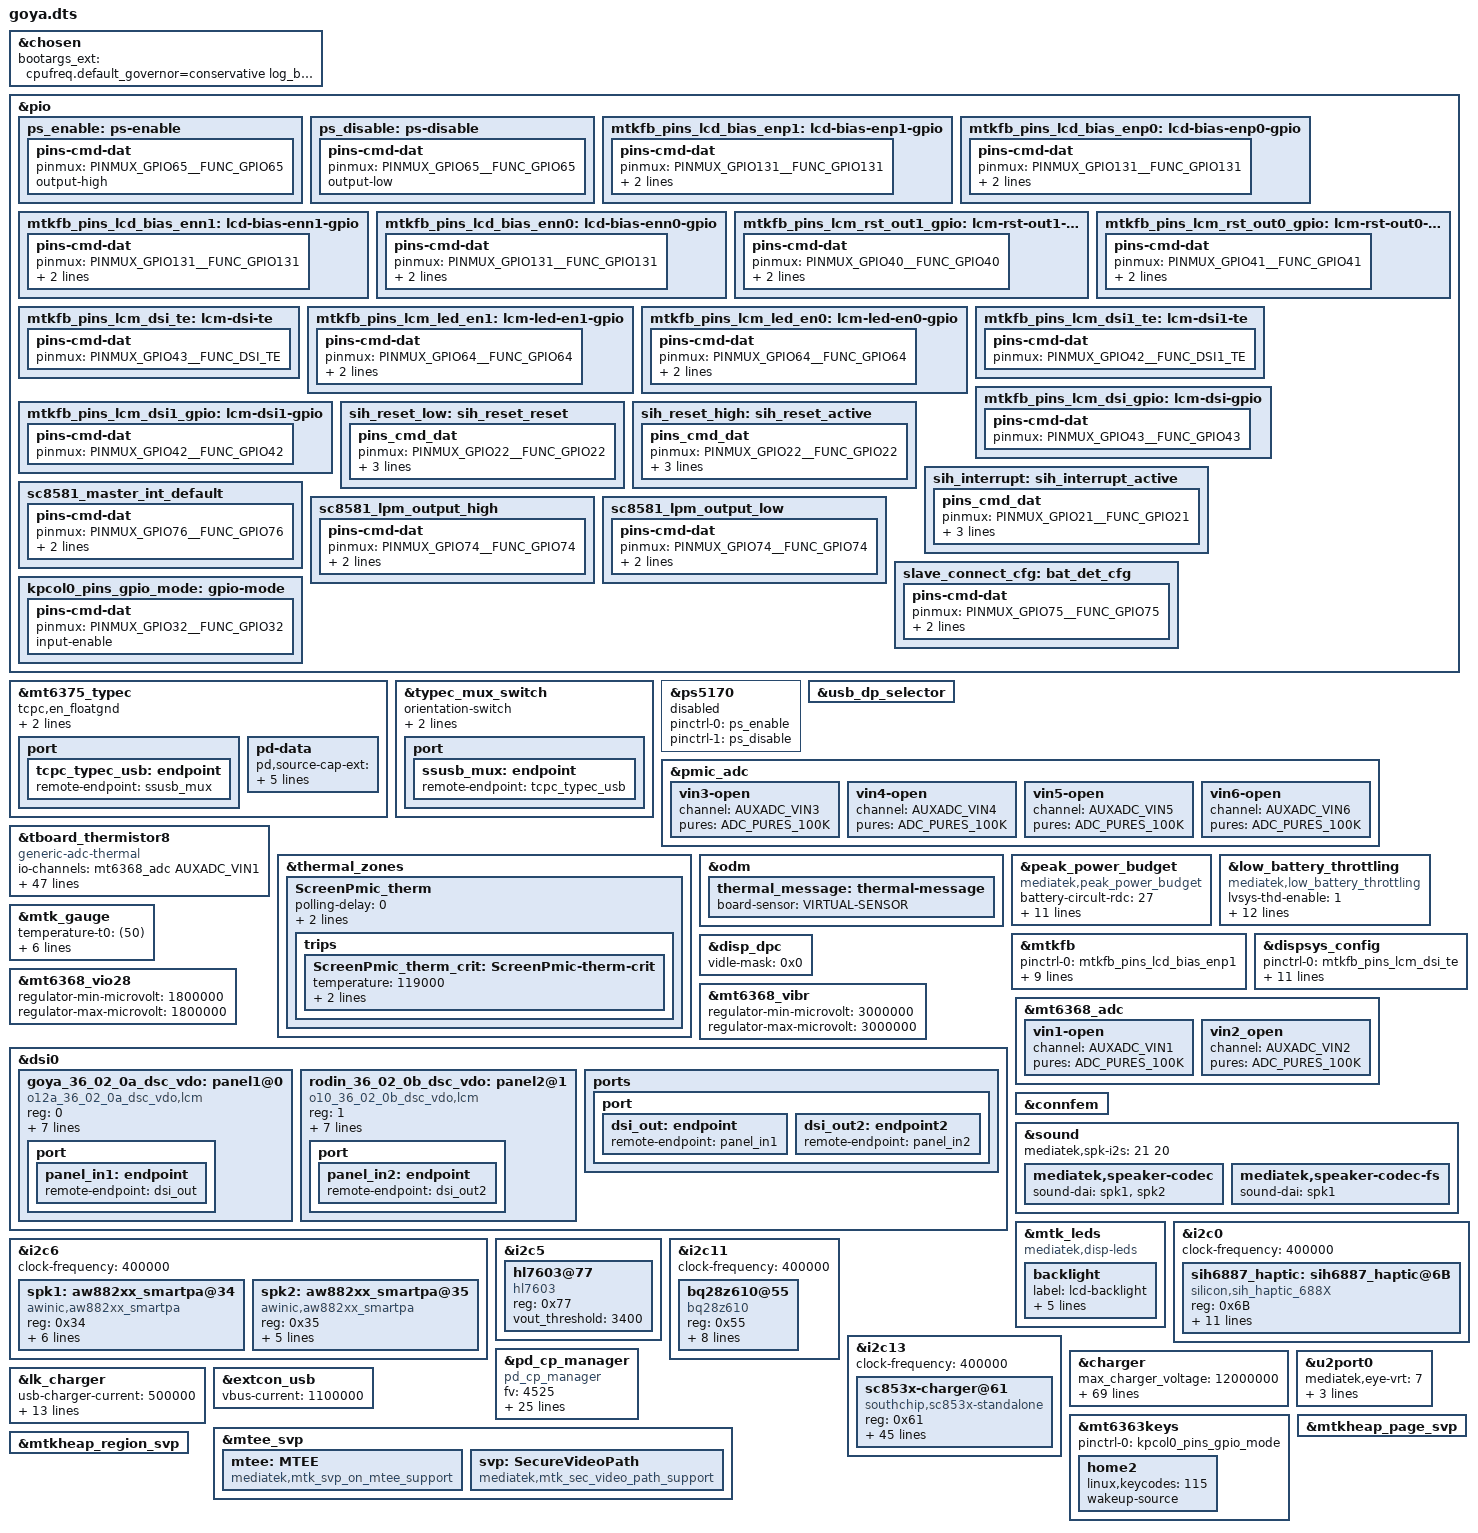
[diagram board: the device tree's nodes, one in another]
// SPDX-License-Identifier: (GPL-2.0 OR MIT)
/*
 * Copyright (C) 2022 MediaTek Inc.
 */
/dts-v1/;
/plugin/;
#include <dt-bindings/interrupt-controller/arm-gic.h>
#include <dt-bindings/interrupt-controller/irq.h>
#include <dt-bindings/phy/phy.h>
#include <dt-bindings/pinctrl/mt6899-pinfunc.h>
#include "mediatek/goya-mt6899-common.dtsi"
#include "mediatek/goya-sensor-common.dtsi"
#include <dt-bindings/iio/mt635x-auxadc.h>
#include <dt-bindings/thermal/thermal.h>
#include "mediatek/xiaomi_goya_t1_chip.dtsi"

&chosen {
	bootargs_ext = "cpufreq.default_governor=conservative \
				log_buf_len=4M";
};

/* usb typec mux start */
&pio {

	ps_enable: ps-enable {
		pins-cmd-dat {
			pinmux = <PINMUX_GPIO65__FUNC_GPIO65>;
			output-high;
		};
	};

	ps_disable: ps-disable {
		pins-cmd-dat {
			pinmux = <PINMUX_GPIO65__FUNC_GPIO65>;
			output-low;
		};
	};

};

&mt6375_typec {
	tcpc,en_floatgnd;
	/* 0:16x, 1:128x, 2:512x, 3:1024x */
	wd,wd0_tsleep = <1>;
	/* 0:400us, 1:1ms, 2:2ms, 3:4ms, 4:10ms, 5:40ms, 6:100ms, 7:400ms */
	wd,wd0_tdet = <3>;
	/* example wd0_tsleep = 512x, wd0_tdet = 4ms, wd0 polling time = 512*4ms */

	port {
		tcpc_typec_usb: endpoint {
			remote-endpoint = <&ssusb_mux>;
		};
	};

	pd-data {
		pd,source-cap-ext = /bits/ 8 <0xcf 0x29 0x75 0x63
					0x00 0x00 0x00 0x00
					0x00 0x00 0x00 0x00
					0x00 0x00 0x00 0x00
					0x00 0x00 0x00 0x00
					0x00 0x00 0x01 0x05
					0x00>;
		pd,sink-cap-ext = /bits/ 8 <0xcf 0x29 0x75 0x63
					0x00 0x00 0x00 0x00
					0x00 0x00 0x01 0x00
					0x00 0x00 0x00 0x00
					0x01 0x0b 0x01 0x37
					0x37 0x00 0x00 0x00>;

		pd,sink-pdo-data = <0x0001912c 0x0002d12c 0xc0dc2464>;
	};
};

&typec_mux_switch {
	orientation-switch;
	mode-switch;
	accessory;
	port {
		ssusb_mux: endpoint {
			remote-endpoint = <&tcpc_typec_usb>;
		};
	};
};

&ps5170 {
	pinctrl-names = "enable", "disable";
	pinctrl-0 = <&ps_enable>;
	pinctrl-1 = <&ps_disable>;
	status = "disable";
};

&usb_dp_selector {
	status = "okay";
};
/* usb typec mux end */

&pmic_adc {
	vin3-open {
		channel = <AUXADC_VIN3>;
		pures = <ADC_PURES_100K>;
	};
	vin4-open {
		channel = <AUXADC_VIN4>;
		pures = <ADC_PURES_100K>;
	};
	vin5-open {
		channel = <AUXADC_VIN5>;
		pures = <ADC_PURES_100K>;
	};
	vin6-open {
		channel = <AUXADC_VIN6>;
		pures = <ADC_PURES_100K>;
	};
};

&tboard_thermistor8 {
	compatible = "generic-adc-thermal";
	#thermal-sensor-cells = <0>;
	io-channels = <&mt6368_adc AUXADC_VIN1>;
	io-channel-names = "sensor-channel";
	temperature-lookup-table =
		<(-40000) 1799>,
		<(-39000) 1797>,
		<(-38000) 1794>,
		<(-37000) 1790>,
		<(-36000) 1787>,
		<(-35000) 1783>,
		<(-34000) 1779>,
		<(-33000) 1775>,
		<(-32000) 1771>,
		<(-31000) 1766>,
		<(-30000) 1761>,
		<(-29000) 1756>,
		<(-28000) 1751>,
		<(-27000) 1745>,
		<(-26000) 1739>,
		<(-25000) 1733>,
		<(-24000) 1726>,
		<(-23000) 1719>,
		<(-22000) 1712>,
		<(-21000) 1705>,
		<(-20000) 1696>,
		<(-19000) 1688>,
		<(-18000) 1678>,
		<(-17000) 1669>,
		<(-16000) 1659>,
		<(-15000) 1649>,
		<(-14000) 1640>,
		<(-13000) 1628>,
		<(-12000) 1617>,
		<(-11000) 1605>,
		<(-10000) 1592>,
		<(-9000) 1580>,
		<(-8000) 1567>,
		<(-7000) 1554>,
		<(-6000) 1539>,
		<(-5000) 1526>,
		<(-4000) 1509>,
		<(-3000) 1493>,
		<(-2000) 1477>,
		<(-1000) 1460>,
		<0 1445>,
		<1000 1427>,
		<2000 1409>,
		<3000 1391>,
		<4000 1373>,
		<5000 1354>,
		<6000 1335>,
		<7000 1314>,
		<8000 1295>,
		<9000 1276>,
		<10000 1255>,
		<11000 1233>,
		<12000 1212>,
		<13000 1190>,
		<14000 1169>,
		<15000 1147>,
		<16000 1125>,
		<17000 1104>,
		<18000 1082>,
		<19000 1059>,
		<20000 1039>,
		<21000 1016>,
		<22000 993>,
		<23000 971>,
		<24000 942>,
		<25000 920>,
		<26000 899>,
		<27000 878>,
		<28000 856>,
		<29000 835>,
		<30000 814>,
		<31000 794>,
		<32000 773>,
		<33000 753>,
		<34000 733>,
		<35000 714>,
		<36000 694>,
		<37000 676>,
		<38000 656>,
		<39000 638>,
		<40000 620>,
		<41000 602>,
		<42000 587>,
		<43000 570>,
		<44000 551>,
		<45000 534>,
		<46000 518>,
		<47000 503>,
		<48000 488>,
		<49000 473>,
		<50000 459>,
		<51000 444>,
		<52000 431>,
		<53000 417>,
		<54000 404>,
		<55000 392>,
		<56000 379>,
		<57000 368>,
		<58000 356>,
		<59000 345>,
		<60000 334>,
		<61000 323>,
		<62000 313>,
		<63000 303>,
		<64000 293>,
		<65000 284>,
		<66000 275>,
		<67000 266>,
		<68000 258>,
		<69000 250>,
		<70000 242>,
		<71000 234>,
		<72000 226>,
		<73000 219>,
		<74000 212>,
		<75000 206>,
		<76000 199>,
		<77000 193>,
		<78000 187>,
		<79000 181>,
		<80000 175>,
		<81000 169>,
		<82000 164>,
		<83000 159>,
		<84000 154>,
		<85000 149>,
		<86000 144>,
		<87000 140>,
		<88000 136>,
		<89000 131>,
		<90000 127>,
		<91000 123>,
		<92000 120>,
		<93000 116>,
		<94000 112>,
		<95000 109>,
		<96000 105>,
		<97000 102>,
		<98000 99>,
		<99000 96>,
		<100000 93>,
		<101000 90>,
		<102000 88>,
		<103000 85>,
		<104000 82>,
		<105000 80>,
		<106000 78>,
		<107000 75>,
		<108000 73>,
		<109000 71>,
		<110000 69>,
		<111000 67>,
		<112000 65>,
		<113000 63>,
		<114000 61>,
		<115000 59>,
		<116000 58>,
		<117000 56>,
		<118000 55>,
		<119000 53>,
		<120000 51>,
		<121000 50>,
		<122000 49>,
		<123000 47>,
		<124000 46>,
		<125000 45>;
};

&thermal_zones {
	ScreenPmic_therm: ScreenPmic_therm {
		polling-delay = <0>; /* milliseconds */
		polling-delay-passive = <0>; /* milliseconds */
		thermal-sensors = <&tboard_thermistor8>;

		trips {
			ScreenPmic_therm_crit: ScreenPmic-therm-crit {
				temperature = <119000>;
				hysteresis = <2000>;
				type = "passive";
			};
		};
	};
};

&odm {
	thermal_message: thermal-message {
		board-sensor = "VIRTUAL-SENSOR";
	};
};


&peak_power_budget {
	compatible = "mediatek,peak_power_budget";

	battery-circult-rdc = <27>;
	battery0-path-rac-t0 = <57>;
	battery0-path-rac-t1 = <57>;
	battery0-path-rac-t2 = <57>;
	battery0-path-rac-t3 = <57>;
	battery0-path-rac-t4 = <57>;
	battery0-path-rac-t5 = <57>;
	max-temperature-stage = <5>;
	temperature-threshold = <50 25 10 0 0xFFFFFFF6>;
	system-ocp = <13000>;
	system-uvlo = <2400>;
	bat-ocv-table-num = <0>;
};

&low_battery_throttling {
	compatible = "mediatek,low_battery_throttling";
	lvsys-thd-enable = <1>;
	vbat-thd-enable = <1>;
	bat0-thd-volts-l = <
		3325 3100 2900
		3450 3100 2900
		3699 3100 2900
		4323 3272 2988>;
	bat0-thd-volts-h = <
		3425 3325 3100
		3550 3450 3100
		3799 3699 3100
		4423 4323 3272>;
	bat1-thd-volts-l = <
		3325 3100 2900
		3450 3100 2900
		3699 3100 2900
		4323 3272 2988>;
	bat1-thd-volts-h = <
		3425 3325 3100
		3550 3450 3100
		3799 3699 3100
		4423 4323 3272>;
	lvsys-thd-volt-l = <2900>;
	lvsys-thd-volt-h = <3100>;
	temperature-stage-threshold = <25 10 0>;
};

&mtk_gauge {
	temperature-t0 = <(50)>;
	/* Battery temperature T0 */
	temperature-t1 = <(25)>;
	/* Battery temperature T1 */
	temperature-t2 = <(10)>;
	/* Battery temperature T2 */
	temperature-t3 = <(0)>;
	/* Battery temperature T3 */
	temperature-t4 = <(-10)>;
	/* Battery temperature T4 */
	active-table = <(5)>;
	#include "goya_mt6899_battery_table.dtsi"
};

&pio {
	mtkfb_pins_lcd_bias_enp1: lcd-bias-enp1-gpio {
		pins-cmd-dat {
			pinmux = <PINMUX_GPIO131__FUNC_GPIO131>;
			slew-rate = <1>;
			output-high;
		};
	};

	mtkfb_pins_lcd_bias_enp0: lcd-bias-enp0-gpio {
		pins-cmd-dat {
			pinmux = <PINMUX_GPIO131__FUNC_GPIO131>;
			slew-rate = <1>;
			output-low;
		};
	};

	mtkfb_pins_lcd_bias_enn1: lcd-bias-enn1-gpio {
		pins-cmd-dat {
			pinmux = <PINMUX_GPIO131__FUNC_GPIO131>;
			slew-rate = <1>;
			output-high;
		};
	};

	mtkfb_pins_lcd_bias_enn0: lcd-bias-enn0-gpio {
		pins-cmd-dat {
			pinmux = <PINMUX_GPIO131__FUNC_GPIO131>;
			slew-rate = <1>;
			output-low;
		};
	};

	mtkfb_pins_lcm_rst_out1_gpio: lcm-rst-out1-gpio {
		pins-cmd-dat {
			pinmux = <PINMUX_GPIO40__FUNC_GPIO40>;
			slew-rate = <1>;
			output-high;
		};
	};

	mtkfb_pins_lcm_rst_out0_gpio: lcm-rst-out0-gpio {
		pins-cmd-dat {
			pinmux = <PINMUX_GPIO41__FUNC_GPIO41>;
			slew-rate = <1>;
			output-low;
		};
	};

	mtkfb_pins_lcm_dsi_te: lcm-dsi-te {
		pins-cmd-dat {
			pinmux = <PINMUX_GPIO43__FUNC_DSI_TE>;
		};
	};

	mtkfb_pins_lcm_led_en1: lcm-led-en1-gpio {
		pins-cmd-dat {
			pinmux = <PINMUX_GPIO64__FUNC_GPIO64>;
			slew-rate = <1>;
			output-high;
		};
	};

	mtkfb_pins_lcm_led_en0: lcm-led-en0-gpio {
		pins-cmd-dat {
			pinmux = <PINMUX_GPIO64__FUNC_GPIO64>;
			slew-rate = <1>;
			output-low;
		};
	};

	mtkfb_pins_lcm_dsi1_te: lcm-dsi1-te {
		pins-cmd-dat {
			pinmux = <PINMUX_GPIO42__FUNC_DSI1_TE>;
		};
	};

	mtkfb_pins_lcm_dsi_gpio: lcm-dsi-gpio {
		pins-cmd-dat {
			pinmux = <PINMUX_GPIO43__FUNC_GPIO43>;
		};
	};

	mtkfb_pins_lcm_dsi1_gpio: lcm-dsi1-gpio {
		pins-cmd-dat {
			pinmux = <PINMUX_GPIO42__FUNC_GPIO42>;
		};
	};
};
&mtkfb {
	pinctrl-names = "lcd_bias_enp1_gpio", "lcd_bias_enp0_gpio",
		"lcd_bias_enn1_gpio", "lcd_bias_enn0_gpio",
		"lcm_rst_out1_gpio", "lcm_rst_out0_gpio",
		"mode_te_te", "lcm_led_en1_gpio", "lcm_led_en0_gpio",
		"mode_te_te1";
	pinctrl-0 = <&mtkfb_pins_lcd_bias_enp1>;
	pinctrl-1 = <&mtkfb_pins_lcd_bias_enp0>;
	pinctrl-2 = <&mtkfb_pins_lcd_bias_enn1>;
	pinctrl-3 = <&mtkfb_pins_lcd_bias_enn0>;
	pinctrl-4 = <&mtkfb_pins_lcm_rst_out1_gpio>;
	pinctrl-5 = <&mtkfb_pins_lcm_rst_out0_gpio>;
	pinctrl-6 = <&mtkfb_pins_lcm_dsi_te>;
	pinctrl-7 = <&mtkfb_pins_lcm_led_en1>;
	pinctrl-8 = <&mtkfb_pins_lcm_led_en0>;
	pinctrl-9 = <&mtkfb_pins_lcm_dsi1_te>;

	status = "okay";
};

&dispsys_config {
	pinctrl-names = "mode_te_te", "mode_te_te1";
	pinctrl-0 = <&mtkfb_pins_lcm_dsi_te>;
	pinctrl-1 = <&mtkfb_pins_lcm_dsi1_te>;
	status = "okay";
	lk_mode_index = <0>;
	no_hwc_layers = <2>;
	no_hwc_overlap = <1>;
	bypass-pc-path = <1>;

	helper-value = <0>, /*MTK_DRM_OPT_STAGE*/
				<1>, /*MTK_DRM_OPT_USE_CMDQ*/
				<1>, /*MTK_DRM_OPT_USE_M4U*/
				<1>, /*MTK_DRM_OPT_MMQOS_SUPPORT*/
				<1>, /*MTK_DRM_OPT_MMDVFS_SUPPORT*/
				<0>, /*MTK_DRM_OPT_SODI_SUPPORT*/
				<1>, /*MTK_DRM_OPT_IDLE_MGR*/
				<0>, /*MTK_DRM_OPT_IDLEMGR_SWTCH_DECOUPLE*/
				<1>, /*MTK_DRM_OPT_IDLEMGR_BY_REPAINT*/
				<0>, /*MTK_DRM_OPT_IDLEMGR_ENTER_ULPS*/
				<0>, /*MTK_DRM_OPT_IDLEMGR_KEEP_LP11*/
				<0>, /*MTK_DRM_OPT_DYNAMIC_RDMA_GOLDEN_SETTING*/
				<1>, /*MTK_DRM_OPT_IDLEMGR_DISABLE_ROUTINE_IRQ*/
				<1>, /*MTK_DRM_OPT_IDLEMGR_ASYNC*/
				<0>, /*MTK_DRM_OPT_MET_LOG*/
				<1>, /*MTK_DRM_OPT_USE_PQ*/
				<1>, /*MTK_DRM_OPT_ESD_CHECK_RECOVERY*/
				<1>, /*MTK_DRM_OPT_ESD_CHECK_SWITCH*/
				<1>, /*MTK_DRM_OPT_PRESENT_FENCE*/
				<0>, /*MTK_DRM_OPT_RDMA_UNDERFLOW_AEE*/
				<1>, /*MTK_DRM_OPT_DSI_UNDERRUN_AEE*/
				<1>, /*MTK_DRM_OPT_DSI_UNDERRUN_AEE_V2*/
				<0>, /*MTK_DRM_OPT_ODDMR_UNDERRUN_AEE*/
				<1>, /*MTK_DRM_OPT_HRT*/
				<1>, /*MTK_DRM_OPT_HRT_MODE*/
				<0>, /*MTK_DRM_OPT_DELAYED_TRIGGER*/
				<1>, /*MTK_DRM_OPT_OVL_EXT_LAYER*/
				<1>, /*MTK_DRM_OPT_AOD*/
				<1>, /*MTK_DRM_OPT_RPO*/
				<0>, /*MTK_DRM_OPT_DUAL_PIPE*/
				<0>, /*MTK_DRM_OPT_DC_BY_HRT*/
				<1>, /*MTK_DRM_OPT_OVL_WCG*/
				<0>, /*MTK_DRM_OPT_OVL_SBCH*/
				<1>, /*MTK_DRM_OPT_COMMIT_NO_WAIT_VBLANK*/
				<0>, /*MTK_DRM_OPT_MET*/
				<0>, /*MTK_DRM_OPT_REG_PARSER_RAW_DUMP*/
				<0>, /*MTK_DRM_OPT_VP_PQ*/
				<0>, /*MTK_DRM_OPT_GAME_PQ*/
				<0>, /*MTK_DRM_OPT_MMPATH*/
				<0>, /*MTK_DRM_OPT_HBM*/
				<0>, /*MTK_DRM_OPT_VDS_PATH_SWITCH*/
				<0>, /*MTK_DRM_OPT_LAYER_REC*/
				<1>, /*MTK_DRM_OPT_CLEAR_LAYER*/
				<1>, /*MTK_DRM_OPT_LFR*/
				<0>, /*MTK_DRM_OPT_SF_PF*/
				<0>, /*MTK_DRM_OPT_DYN_MIPI_CHANGE*/
				<0>, /*MTK_DRM_OPT_PRIM_DUAL_PIPE*/
				<0>, /*MTK_DRM_OPT_MSYNC2_0*/
				<1>, /*MTK_DRM_OPT_MML_PRIMARY*/
				<1>, /*MTK_DRM_OPT_MML_SUPPORT_CMD_MODE*/
				<1>, /*MTK_DRM_OPT_MML_PQ*/
				<1>, /*MTK_DRM_OPT_MML_IR*/
				<0>, /*MTK_DRM_OPT_DUAL_TE*/
				<1>, /*MTK_DRM_OPT_RES_SWITCH*/
				<1>, /*MTK_DRM_OPT_RES_SWITCH_ON_AP*/
				<0>, /*MTK_DRM_OPT_PREFETCH_TE*/
				<0>, /*MTK_DRM_OPT_VIDLE_APSRC_OFF*/
				<0>, /*MTK_DRM_OPT_VIDLE_DSI_PLL_OFF*/
				<0>, /*MTK_DRM_OPT_CHECK_TRIGGER_MERGE*/
				<0>, /*MTK_DRM_OPT_VIRTUAL_DISP*/
				<1>, /*MTK_DRM_OPT_OVL_BW_MONITOR*/
				<0>, /*MTK_DRM_OPT_GPU_CACHE*/
				<1>, /*MTK_DRM_OPT_SPHRT*/
				<0>, /*MTK_DRM_OPT_SDPA_OVL_SWITCH*/
				<0>, /*MTK_DRM_OPT_HRT_BY_LARB*/
				<1>, /*MTK_DRM_OPT_MAX_CHANNEL_HRT*/
				<0>, /*MTK_DRM_OPT_TILE_OVERHEAD*/
				<0>, /*MTK_DRM_OPT_VIDLE_TOP_EN*/
				<0>, /*MTK_DRM_OPT_VIDLE_MTCMOS_DT_EN*/
				<0>, /*MTK_DRM_OPT_VIDLE_MMINFRA_DT_EN*/
				<0>, /*MTK_DRM_OPT_VIDLE_DVFS_DT_EN*/
				<0>, /*MTK_DRM_OPT_VIDLE_QOS_DT_EN*/
				<0>, /*MTK_DRM_OPT_VIDLE_GCE_TS_EN*/
				<0>, /*MTK_DRM_OPT_DPC_PRE_TE_EN*/
				<1>, /*MTK_DRM_OPT_PARTIAL_UPDATE*/
				<0>, /*MTK_DRM_OPT_SLC_ALL_CACHE*/
				<1>, /*MTK_DRM_OPT_OVL_WCG_BY_COLOR_MODE*/
				<0>; /*"MTK_DRM_OPT_OVLSYS_CASCADE"*/
};

&disp_dpc {
	vidle-mask = <0x0>;
};

&mt6368_vio28 {
	regulator-min-microvolt = <1800000>;
	regulator-max-microvolt = <1800000>;
};

&mt6368_vibr {
	regulator-min-microvolt = <3000000>;
	regulator-max-microvolt = <3000000>;
};

&dsi0 {
	status = "okay";
	#address-cells = <1>;
	#size-cells = <0>;
	goya_36_02_0a_dsc_vdo: panel1@0 {
		compatible = "o12a_36_02_0a_dsc_vdo,lcm";
		reg = <0>;
		pm-enable-gpios = <&pio 64 0>;
		reset-gpios = <&pio 41 0>;
		mi,esd-err-irq-gpio = <&pio 122 0x2002>;
		vio18-supply = <&mt6368_vio28>;
		vibr30-supply = <&mt6368_vibr>;
		dvdd-gpios = <&pio 131 0>;
		gate-ic = <4831>;
		pinctrl-names = "default";
		port {
			panel_in1: endpoint {
				remote-endpoint = <&dsi_out>;
			};
		};
	};
	rodin_36_02_0b_dsc_vdo: panel2@1 {
		compatible = "o10_36_02_0b_dsc_vdo,lcm";
		reg = <1>;
		pm-enable-gpios = <&pio 64 0>;
		reset-gpios = <&pio 41 0>;
		mi,esd-err-irq-gpio = <&pio 122 0x2002>;
		vio18-supply = <&mt6368_vio28>;
		vibr30-supply = <&mt6368_vibr>;
		dvdd-gpios = <&pio 72 0>;
		gate-ic = <4831>;
		pinctrl-names = "default";
		port {
			panel_in2: endpoint {
				remote-endpoint = <&dsi_out2>;
			};
		};
	};
	ports {
		port {
			dsi_out: endpoint {
				remote-endpoint = <&panel_in1>;
			};
			dsi_out2: endpoint2 {
				remote-endpoint = <&panel_in2>;
			};
		};
	};
};


&mt6368_adc {
	vin1-open {
		channel = <AUXADC_VIN1>;
		pures = <ADC_PURES_100K>;
	};
	vin2_open {
		channel = <AUXADC_VIN2>;
		pures = <ADC_PURES_100K>;
	};
};

&connfem {
/* Enable epa_elna node to support Wifi & BT ePA/eLNA FEM on customer load */
#if 0
	epa-elna {
		parts = <&wlan7207h &wlan7207c>;
		wifi {
			flags-0 {
				open-loop;
			};
		};
		bt {
			flags-0 {
				/* choose one of: epa-elna/epa/elna/bypass */
				epa-elna;
			};
		};
	};
#endif
};

&i2c6 {
/*
	spk1: speaker_amp@5c {
		compatible = "richtek,rt5512";
		#sound-dai-cells = <0>;
		reg = <0x5c>;
		status = "okay";
		sound-name-prefix = "Left";
	};
*/
	clock-frequency = <400000>;
	spk1: aw882xx_smartpa@34 {
		compatible = "awinic,aw882xx_smartpa";
		#sound-dai-cells = <0>;
		reg = <0x34>;
		reset-gpio = <&pio 64 0>;
		irq-gpio = <&pio 19 0x0>;
		spk-sw-gpio = <&pio 23 0x0>;
		sound-channel = <0>;
		aw-re-min = <5500>;
		aw-re-max= <8000>;
		/*aw-cali-mode = "none";*/
		status = "okay";
	};
	spk2: aw882xx_smartpa@35 {
		compatible = "awinic,aw882xx_smartpa";
		#sound-dai-cells = <0>;
		reg = <0x35>;
		reset-gpio = <&pio 63 0>;
		irq-gpio = <&pio 20 0x0>;
		sound-channel = <1>;
		aw-re-min = <5000>;
		aw-re-max= <7500>;
		/*aw-cali-mode = "none";*/
		status = "okay";
	};
};

&sound {
	mediatek,spk-i2s = <21 20>;
	mediatek,speaker-codec {
		sound-dai = <&spk1>, <&spk2>;
	};
	mediatek,speaker-codec-fs {
		sound-dai = <&spk1>;
	};
};

&mtk_leds {
	compatible = "mediatek,disp-leds";

	backlight {
		label = "lcd-backlight";
		max-brightness = <16383>;
		min-brightness = <1>;
		max-hw-brightness = <16383>;
		led-mode = <4>;
		default-state = "FifteenPercent";
	};
};

#if 0
&mtk_leds {
	compatible = "mediatek,disp-leds";

	backlight {
		label = "lcd-backlight";
		max-brightness = <4095>;
		min-brightness = <4>;
		max-hw-brightness = <4095>;
		led-mode = <4>;
		default-state = "quarter";
	};
};

&pdc {
	pd-vbus-upper-bound = <9000000>;
};

&dsi1 {
//	status = "okay";
	#address-cells = <1>;
	#size-cells = <0>;
	init-panel-off;
	panel1@0 {
		compatible = "truly,td4330,cmd";
		reg = <0>;
		pm-enable-gpios = <&pio 215 0>;
		reset-gpios = <&pio 9 0>;
		swap-from-dts;
		lane-swap-setting = <1 2 0 3 4 2>;
		pn-swap-setting = <1 1 1 1 1 1>;
		gate-ic = <4831>;
		pinctrl-names = "default";
		port {
			panel1_in: endpoint {
				remote-endpoint = <&dsi1_out>;
			};
		};
	};
	panel2@1 {
		compatible = "jdi,nt36672e,vdo,120hz";
		reg = <1>;
		pm-enable-gpios = <&pio 215 0>;
		reset-gpios = <&pio 9 0>;
		swap-from-dts;
		gate-ic = <4831>;
		pinctrl-names = "default";
		port {
			panel2_in: endpoint {
				remote-endpoint = <&dsi1_out2>;
			};
		};
	};
	panel3@2 {
		compatible = "jdi,nt36672e,cphy,vdo";
		reg = <2>;
		pm-enable-gpios = <&pio 215 0>;
		reset-gpios = <&pio 9 0>;
		gate-ic = <4831>;
		pinctrl-names = "default";
		port {
			panel3_in: endpoint {
				remote-endpoint = <&dsi1_out3>;
			};
		};
	};
	panel4@3 {
		compatible = "jdi,nt36672e,vdo,60hz";
		reg = <3>;
		pm-enable-gpios = <&pio 215 0>;
		reset-gpios = <&pio 9 0>;
		gate-ic = <4831>;
		pinctrl-names = "default";
		port {
			panel4_in: endpoint {
				remote-endpoint = <&dsi1_out4>;
			};
		};
	};
	ports {
		port {
			dsi1_out: endpoint@0 {
				remote-endpoint = <&panel1_in>;
			};

			dsi1_out2: endpoint@1 {
				remote-endpoint = <&panel2_in>;
			};

			dsi1_out3: endpoint@2 {
				remote-endpoint = <&panel3_in>;
			};

			dsi1_out4: endpoint@3 {
				remote-endpoint = <&panel4_in>;
			};
		};
	};
};

&dsi1_te {
	interrupt-parent = <&pio>;
	interrupts = <10 1 10 1>;
	status = "okay";
};

#if 1
/* GPS GPIO standardization start */
&pio {
	gps_pins_default: gps_default {
	};
	gps_l1_lna_pins_ol: gps-l1-lna0 {
		pins-cmd-dat {
			pinmux = <PINMUX_GPIO190__FUNC_GPIO12>;
			output-low;
		};
	};
	gps_l1_lna_pins_dsp_ctrl: gps-l1-lna1 {
		pins-cmd-dat {
			pinmux = <PINMUX_GPIO190__FUNC_GPS_L1_ELNA_EN>;
		};
	};
	gps_l1_lna_pins_oh: gps-l1-lna2 {
		pins-cmd-dat {
			pinmux = <PINMUX_GPIO190__FUNC_GPIO12>;
			output-high;
		};
	};
	gps_l5_lna_pins_ol: gps-l5-lna0 {
		pins-cmd-dat {
			pinmux = <PINMUX_GPIO191__FUNC_GPIO13>;
			output-low;
		};
	};
	gps_l5_lna_pins_dsp_ctrl: gps-l5-lna1 {
		pins-cmd-dat {
			pinmux = <PINMUX_GPIO191__FUNC_GPS_L5_ELNA_EN>;
		};
	};
	gps_l5_lna_pins_oh: gps-l5-lna2 {
		pins-cmd-dat {
			pinmux = <PINMUX_GPIO191__FUNC_GPIO13>;
			output-high;
		};
	};
};
&gps {
	pinctrl-names = "default",
		"gps_l1_lna_disable",
		"gps_l1_lna_dsp_ctrl",
		"gps_l1_lna_enable",
		"gps_l5_lna_disable",
		"gps_l5_lna_dsp_ctrl",
		"gps_l5_lna_enable";
	pinctrl-0 = <&gps_pins_default>;
	pinctrl-1 = <&gps_l1_lna_pins_ol>;
	pinctrl-2 = <&gps_l1_lna_pins_dsp_ctrl>;
	pinctrl-3 = <&gps_l1_lna_pins_oh>;
	pinctrl-4 = <&gps_l5_lna_pins_ol>;
	pinctrl-5 = <&gps_l5_lna_pins_dsp_ctrl>;
	pinctrl-6 = <&gps_l5_lna_pins_oh>;
	status = "okay";
};
/* GPS GPIO standardization end */
#endif

&pcie0 {
	pinctrl-names = "default", "sleep", "work";
	pinctrl-0 = <&pcie0_pins_default>;
	pinctrl-1 = <&pcie0_pins_sleep>;
	pinctrl-2 = <&pcie0_pins_work>;
	max-link-speed = <3>;
	status = "okay";
};

&pcie1 {
	pinctrl-names = "default";
	pinctrl-0 = <&pcie1_pins_default>;
	status = "disabled";
};

&pciephy0 {
	status = "okay";
};

&pciephy1 {
	status = "disabled";
};

/* PCIe pinmux start */
&pio {
	pcie0_pins_default: pcie0-default {
		pins-cmd-dat {
			pinmux = <PINMUX_GPIO143__FUNC_GPIO143>;
			output-low;
		};

		pins-cmd-dat1 {
			pinmux = <PINMUX_GPIO144__FUNC_GPIO144>,
				 <PINMUX_GPIO145__FUNC_GPIO145>;
			bias-pull-up;
			input-enable;
		};
	};

	pcie0_pins_work: pcie0-work {
		pins-cmd-dat {
			pinmux = <PINMUX_GPIO143__FUNC_PCIE_PERSTN>,
				 <PINMUX_GPIO145__FUNC_PCIE_CLKREQN>;
			bias-pull-up;
		};

		pins-cmd-dat1 {
			pinmux = <PINMUX_GPIO144__FUNC_GPIO144>;
			bias-pull-down;
			input-enable;
		};
	};

	pcie0_pins_sleep: pcie0-sleep {
		pins-cmd-dat {
			pinmux = <PINMUX_GPIO143__FUNC_GPIO143>;
			output-low;
		};

		pins-cmd-dat1 {
			pinmux = <PINMUX_GPIO144__FUNC_GPIO144>,
				 <PINMUX_GPIO145__FUNC_GPIO145>;
			bias-pull-up;
			input-enable;
		};
	};

	pcie1_pins_default: pcie1-default {
		pins-cmd-dat {
			pinmux = <PINMUX_GPIO2__FUNC_PCIE_CLKREQN_P1>,
				 <PINMUX_GPIO3__FUNC_PCIE_WAKEN_P1>,
				 <PINMUX_GPIO4__FUNC_PCIE_PERSTN_P1>;
			bias-pull-up;
		};
	};
};
/* PCIe pinmux end */

/* usb typec mux start */
&pio {

	ps_enable: ps_enable {
		pins_cmd_dat {
			pinmux = <PINMUX_GPIO111__FUNC_GPIO111>;
			output-high;
		};
	};

	ps_disable: ps_disable {
		pins_cmd_dat {
			pinmux = <PINMUX_GPIO111__FUNC_GPIO111>;
			output-low;
		};
	};

};

&mt6375_typec {
	port {
		tcpc_typec_usb: endpoint {
			remote-endpoint = <&ssusb_mux>;
		};
	};
};

&typec_mux_switch {
	orientation-switch;
	mode-switch;
	accessory;
	port {
		ssusb_mux: endpoint {
			remote-endpoint = <&tcpc_typec_usb>;
		};
	};
};

&ps5170 {
	pinctrl-names = "enable", "disable";
	pinctrl-0 = <&ps_enable>;
	pinctrl-1 = <&ps_disable>;
	status = "disable";
};

&usb_dp_selector {
	status = "okay";
};
/* usb typec mux end */

#if 0
&pdc {
	pd_vbus_upper_bound = <12000000>;
};
#endif

&wifi {
	flavor-bin = "dx3";
};

&bt {
	flavor-bin = "dx3";
};

#endif

/* SI Haptic */
&pio {
	sih_reset_low: sih_reset_reset {
		pins_cmd_dat {
			pinmux = <PINMUX_GPIO22__FUNC_GPIO22>;
			drive-strength = <2>;
			bias-disable;
			output-low;
		};
	};
	sih_reset_high: sih_reset_active {
		pins_cmd_dat {
			pinmux = <PINMUX_GPIO22__FUNC_GPIO22>;
			drive-strength = <2>;
			bias-disable;
			output-high;
		};
	};
	sih_interrupt: sih_interrupt_active {
		pins_cmd_dat {
			pinmux = <PINMUX_GPIO21__FUNC_GPIO21>;
			drive-strength = <2>;
			bias-pull-up;
			input-enable;
		};
	};
};
/* SI Haptic */

&i2c0 {
    clock-frequency = <400000>;
	status = "ok";
	/* SI Haptic */
	sih6887_haptic:sih6887_haptic@6B{
		compatible = "silicon,sih_haptic_688X";
		reg = <0x6B>;
		reset-gpio = <&pio 22 0>;
		irq-gpio = <&pio 21 0>;
		interrupt=<26 1>;
		pinctrl-names = "sih_reset_reset","sih_reset_active","sih_interrupt_active";
		pinctrl-0 = <&sih_reset_low>;
		pinctrl-1 = <&sih_reset_high>;
		pinctrl-2 = <&sih_interrupt>;
		lra_name = "0809";
		vib_effect_id_boundary = < 10 >;
		vib_effect_max = < 197 >;
		vib_f0_pre = < 1700 >;
		vib_bst_vol_default = < 95 >;
    };
	/* SI Haptic */
};

/* charger start */
&pio {
	sc8581_master_int_default: sc8581_master_int_default {
		pins-cmd-dat {
			pinmux = <PINMUX_GPIO76__FUNC_GPIO76>;
			bias-pull-up = <MTK_PUPD_SET_R1R0_10>;
			input-enable;
		};
	};

	sc8581_lpm_output_high: sc8581_lpm_output_high {
		pins-cmd-dat {
			pinmux = <PINMUX_GPIO74__FUNC_GPIO74>;
			slew-rate = <1>;
			output-high;
		};
	};

	sc8581_lpm_output_low: sc8581_lpm_output_low {
		pins-cmd-dat {
			pinmux = <PINMUX_GPIO74__FUNC_GPIO74>;
			slew-rate = <1>;
			output-low;
		};
	};
};

&i2c5 {
	status = "ok";
	hl7603@77 {
		compatible = "hl7603";
		reg = <0x77>;
		vout_threshold = <3400>;
	};
};

&pio {
	slave_connect_cfg: bat_det_cfg {
		pins-cmd-dat {
			pinmux = <PINMUX_GPIO75__FUNC_GPIO75>;
			bias-pull-up = <MTK_PUPD_SET_R1R0_10>;
			input-enable;
		};
	};
};


&i2c11 {
	clock-frequency = <400000>;
	status = "okay";
	bq28z610@55 {
		compatible = "bq28z610";
		reg = <0x55>;
		enable_shutdown_delay;
		normal_shutdown_vbat_1s = <3400>;
 		critical_shutdown_vbat_1s = <3340>;
		report_full_rsoc_1s = <9700>;
 		soc_gap_1s = <2>;
 		slave_connect_gpio = <&pio 39 0x1>;
		soc_decimal_rate = <
 			0  38
 			10 35
 			20 33
 			30 33
 			40 33
			50 33
 			60 33
 			70 30
 			80 25
 			90 20
 			95 10 >;
	};
};

&i2c13 {
	clock-frequency = <400000>;
	status = "okay";
	sc853x-charger@61{
		compatible = "southchip,sc853x-standalone";
		reg = <0x61>;
		sc853x,intr_gpio = <&pio 76 IRQ_TYPE_EDGE_FALLING>;
		charger_name = "primary_dvchg";
		charger_name_v4_19 = "primary_dvchg";

		sc,sc853x,vbat-ovp-dis = <0>;
		sc,sc853x,vbat-ovp = <90>; /*3840 + val * 10*/
		sc,sc853x,ibat-ocp-dis = <1>;
		sc,sc853x,ibat-ocp = <100>; /*val * 100*/
		sc,sc853x,vbus-ovp-dis = <0>;
		sc,sc853x,vbus-ovp = <7>; /*9250 + val * 250*/
		sc,sc853x,vac-ovp-dis = <0>;
		sc,sc853x,vac-ovp = <2>; /*0:6.5V 1:11V 2:12V 3:13V 4:14V 5~7:15V*/
		sc,sc853x,ibus-ocp-dis = <1>;
		sc,sc853x,ibus-ocp = <125>; /*val * 50*/
		sc,sc853x,pmid2out-ovp-dis = <0>;
		sc,sc853x,pmid2out-ovp = <2>; /*400 + val * 100*/
		sc,sc853x,pmid2out-uvp-dis = <0>;
		sc,sc853x,pmid2out-uvp = <3>; /*100 + val * 50*/
		sc,sc853x,ibatreg = <0>; /*200 + val * 100*/
		sc,sc853x,ibusreg = <0>; /*100 + val * 50*/
		sc,sc853x,vbatreg = <0>; /*50 + val * 50*/
		sc,sc853x,tdiereg = <3>; /*0:90°C 1:100°C 2:110°C 3:120°C*/
		sc,sc853x,them-flt = <24>; /*val * 25*/
		sc,sc853x,ibat-sns-res = <0>; /*0:2hmo 1:5hmo*/
		sc,sc853x,pmid-pd-en = <0>;
		sc,sc853x,vbus-pd-en = <0>;
		sc,sc853x,work-mode = <0>; /*0: 2:1charge   1: 1:1charge
									 2: 1:2converte 3: 1:1converte*/
		sc,sc853x,ss-timeout = <7>; /*0:disable 1:10ms 2:20ms 3:400ms
									4:80ms 5:320ms 6:1.28s 7:10.24s*/
		sc,sc853x,wd-timeout-dis = <1>;
		sc,sc853x,wd-timeout = <0>; /*0:0.5s 1:1s 2:5s 3:30s*/
		sc,sc853x,vout-ovp-dis = <0>;
		sc,sc853x,vout-ovp = <3>; /*4700 + val * 100*/
		sc,sc853x,fsw-freq = <7>; /*500 + val * 100*/
		sc,sc853x,pin-diag-fall-dis = <0>;
		sc,sc853x,them-flt-dis = <1>;
		sc,sc853x,tshut-dis = <1>;
		sc,sc853x,vbus-in-range-dis = <0>;
		sc,sc853x,ibus-ucp-dis = <0>;
		sc,sc853x,ibat-reg-dis = <0>;
		sc,sc853x,ibus-reg-dis = <0>;
		sc,sc853x,vbat-reg-dis = <0>;
		sc,sc853x,tdie-reg-dis = <1>;
		sc,sc853x,ibat-ocp-dg = <0>; /*0:160us 1:80us 2:320us 3:5ms*/
		sc,sc853x,ibus-ucp-fall-dg = <1>; /*0:8us 1:5ms 2:40ms 3:160ms*/
		sc,sc853x,ibus-ocp-dg = <0>; /*0:160us 1:80us 2:320us 3:5ms*/
		sc,sc853x,vbat-ovp-dg = <0>; /*0:8us 1:160us 2:320us 3:5ms*/
	};
};

&charger {
		max_charger_voltage = <12000000>;
		fv = <4530>;
		fv_normal = <4510>;
		fv_ffc = <4580>;
		iterm = <295>;
		iterm_warm = <295>;
		/* charging current */
		usb_charger_current = <500000>;
		ac_charger_current = <1600000>;
		ac_charger_input_current = <1600000>;
		charging_host_charger_current = <900000>;
		ffc_low_tbat = <200>;
		ffc_medium_tbat = <300>;
		ffc_warm_tbat = <350>;
		ffc_little_high_tbat = <400>;
		ffc_high_tbat = <480>;
		ffc_high_soc = <95>;
		adapter_power = <67>;
		step_fallback_hyst = <25>;
		step_forward_hyst = <5>;
		jeita_fallback_hyst = <10>;
		jeita_forward_hyst = <10>;
		mt6368_moscon1_control;
		en_floatgnd;
		rust_support;
		enable_pdtest_mode = <1>;
		pd2_input_current = <1700000>;
		min_charger_voltage_1 = <4600000>;
		min_charger_voltage_2 = <4600000>;
		sbu_uart_en = <&pio 24 0x0>;
		jeita_fcc_cfg = <(-100)	30	4200	900	753
				31	80	4530	2575	2575
				81	130	4530	3645	3645
				131	200	4530	6320	6320
				201	470	4150	12400	12400
				471	600	4100	2575	2575>;
		jeita_fv_cfg = <(-100)	30	4530
				31	80	4530
				81	130	4530
				131	200	4530
				201	470	4580
				471	600	4100>;

		iterm_ffc_1_cycle = <1773>;
		iterm_ffc_little_warm_1_cycle = <2303>;
		iterm_ffc_warm_1_cycle = <2657>;
		iterm_ffc_hot_1_cycle = <3012>;

		step_chg_cfg_1_cycle = <3000	4150	12300
					4151	4300	9530
					4301	4480	7925
					4481	4580	6320>;

		step_chg_cfg_100_cycle = <3000	4120	12300
					4121	4270	9530
					4271	4460	7925
					4461	4560	6320>;

		step_chg_cfg_300_cycle = <3000  4120    12300
					4121    4270    9530
					4271    4450    7925
					4451    4550    6320>;

		step_chg_cfg_800_cycle = <3000  4120    9820
					4121    4270    7604
					4271    4450    6320
					4451    4550    5036>;

		step_chg_cfg_1000_cycle = <3000	4100	9820
					4101	4250	7604
					4251	4430	6320
					4431	4550	5036>;

		thermal_limit_dcp = <1900 1900 1900 1900 1900 1900 1900 1900 1900 1900 1900 1900 1500 1400 1200 500>;
		thermal_limit_qc2 = <2500 2500 2500 2500 2500 2500 2500 2500 2500 2500 2500 2000 1500 1500 1000 500>;
		thermal_limit_qc3_18w = <2500 2500 2500 2500 2500 2500 2400 2300 2200 2100 1500 1000 800 700 600 500>;
		thermal_limit_qc3_27w = <2500 2500 2500 2500 2500 2500 2400 2300 2200 2100 1500 1000 800 700 600 500>;
		thermal_limit_qc35 = <2500 2500 2500 2500 2500 2500 2400 2300 2200 2100 1500 1000 800 700 600 500>;
		thermal_limit_pd = <12400 10000 8800 8000 6600 6000 5500 5000 4400 3000 2600 2200 1900 1500 1000 300>;

		smart_bypass_support;
		smart_bypass_entry_soc = <20>;
		smart_bypass_exit_soc = <90>;
		smart_bypass_fallback_hyst = <5>; // board_temp(0.1 degree) hyst
		smart_bypass_forward_hyst = <5>;
		smart_bypass_high_lmt_cfg = <(-100)	250	3000
				251	280	2500
				281	300	2000
				301	330	1600
				331	370	1200
				371	800	900>;
		smart_bypass_med_lmt_cfg = <(-100)	150	12400
				151	200	12400
				201	250	12400
				251	300	6000
				301	370	4400
				371	800	1900>;
		smart_bypass_low_lmt_cfg = <(-100)	150	12400
				151	200	12400
				201	250	12400
				251	300	12400
				301	370	12400
				371	800	12400>;
};

&lk_charger {
 	/* charging current */
 	usb-charger-current = <500000>;
 	ac-charger-current = <1500000>;
 	ac-charger-input-current = <2000000>;
 	non-std-ac-charger-current = <1500000>;
 	charging-host-charger-current = <1500000>;
 	ta-ac-charger-current = <1500000>;
 	pd-charger-current = <1500000>;
 	/* battery temperature protection */
 	temp-t4-threshold = <60>;
 	temp-t3-threshold = <45>;
 	pre-charger-current = <400000>;
 	fast-charge-voltage = <3100>;
 	max-charger-voltage = <12000000>;
 	shutdown-voltage = <3200>;
	boot-battery-voltage = <3400000>;
};

&pd_cp_manager {
	compatible = "pd_cp_manager";
	fv = <4525>;
	fv_ffc = <4572>;
	max_fcc = <12400>;
	max_vbus = <12000>;
	max_ibus = <6200>;
	fcc_low_hyst = <150>;
	fcc_high_hyst = <10>;
	low_tbat = <100>;
	high_tbat = <480>;
	high_vbat = <4400>;
	high_soc = <95>;
	low_fcc = <2000>;
	cv_vbat = <4510>;
	cv_vbat_ffc = <4580>;
	cv_ibat = <2000>;
	cv_ibat_bypass = <1300>;
	vbus_low_gap_div = <400>;
	vbus_high_gap_div = <600>;
	min_pdo_vbus = <8000>;
	max_pdo_vbus = <11000>;
//	mt6375_control_gpio = <&pio 77 0x0>;
	support_pmic_parachg;
	switch1_1_enter = <3000>;
	switch1_1_exit = <4000>;
	pdm_ibus_gap = <600>;
	pdm_bypass_ibus_gap = <2600>;
	adapter_power = <67>;
};

&mtk_gauge {
	DISABLE_MTKBATTERY = <(1)>;
};

&u2port0{
	mediatek,eye-vrt = <7>;
	mediatek,eye-term = <7>;
	mediatek,rev6 = <1>;
	mediatek,discth = <0xb>;
};

&extcon_usb {
	vbus-current = <1100000>;
};
/* charger end */

&mt6363keys {
  pinctrl-names = "kpcol0_mode";
  pinctrl-0 = <&kpcol0_pins_gpio_mode>;
  home2 {
    linux,keycodes = <115>;
    wakeup-source;
  };
};

&pio {
  kpcol0_pins_gpio_mode: gpio-mode {
    pins-cmd-dat {
      pinmux = <PINMUX_GPIO32__FUNC_GPIO32>;
      input-enable;
    };
  };
};

&mtee_svp {
	mtee: MTEE {
		compatible = "mediatek,mtk_svp_on_mtee_support";
	};

	svp: SecureVideoPath {
		compatible = "mediatek,mtk_sec_video_path_support";
	};
};

&mtkheap_page_svp {
	status = "ok";
};

&mtkheap_region_svp {
	status = "ok";
};

#include "mediatek/cust_k6899_connfem.dtsi"
#include "mediatek/goya_mt6899_camera_v4l2.dtsi"
#include "mediatek/xiaomi_goya_mt6899_mitee.dtsi"
#include <goya/cust.dtsi>
#include "mediatek/cust_mt6899_nfc_nxp.dtsi"
#include "mediatek/xiaomi_goya_mt6899_fingerprint.dtsi"
#include "mediatek/xiaomi_goya_mt6899_touch.dtsi"

/*End of this file, DO NOT ADD ANYTHING HERE*/
